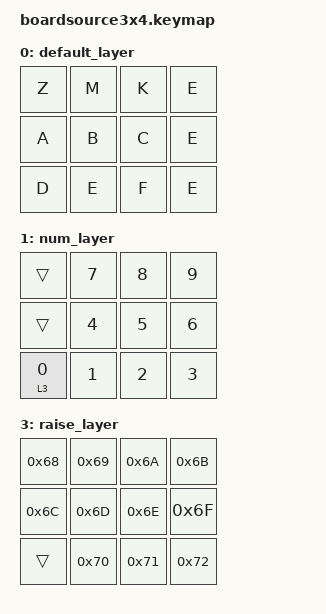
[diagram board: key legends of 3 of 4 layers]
#include <behaviors.dtsi>
#include <dt-bindings/zmk/keys.h>
#include <dt-bindings/zmk/bt.h>

/ {
    keymap {
        compatible = "zmk,keymap";

        default_layer { // Layer 0
            // -------------------------------------------------
            // |     Z     |     M     |     K     |     E     |
            // |     A     |     B     |     C     |     E     |
            // |     D     |     E     |     F     |     E     |
            bindings = <
                &kp Z    &kp M    &kp K    &kp E
                &kp A    &kp B    &kp C    &kp E
                &kp D    &kp E    &kp F    &kp E
            >;
        };

        num_layer {
            bindings = <
                &trans   &kp N7 &kp N8 &kp N9
                &trans   &kp N4 &kp N5 &kp N6
                &lt 3 N0 &kp N1 &kp N2 &kp N3
            >;
        };

        lower_layer {
            bindings = <
                &bt BT_CLR &none        &sys_reset       &bootloader                    &sys_reset
                &trans                  &bt BT_SEL 3     &bt BT_SEL 4 &none             &sys_reset
                &none                   &bt BT_SEL 0     &bt BT_SEL 1 &bt BT_SEL 2      &sys_reset
            >;
        };

        raise_layer {
            bindings = <
                &kp 0x68 &kp 0x69 &kp 0x6A &kp 0x6B
                &kp 0x6C &kp 0x6D &kp 0x6E &kp 0x6F
                &trans   &kp 0x70 &kp 0x71 &kp 0x72
            >;
        };
    };
};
